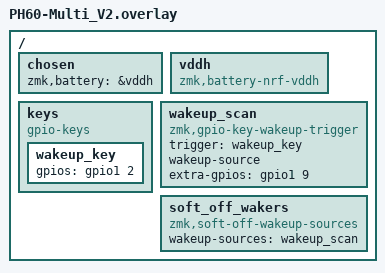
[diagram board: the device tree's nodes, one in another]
/*
 * Copyright (c) 2025 Team PHDesign
 *
 * SPDX-License-Identifier: MIT
 */

#include "PH60-Multi_V2.dtsi"


/ {
	chosen {
		zmk,battery = &vddh;
	};

	vddh: vddh {
		compatible = "zmk,battery-nrf-vddh";
	};

	keys {
		compatible = "gpio-keys";
		wakeup_key: wakeup_key {
			gpios = <&gpio1 2 (GPIO_ACTIVE_HIGH | GPIO_PULL_DOWN)>;  // Row 2
		};
	};

	wakeup_scan: wakeup_scan {
		compatible = "zmk,gpio-key-wakeup-trigger";
		trigger = <&wakeup_key>;
		wakeup-source;
		extra-gpios = <&gpio1 9 GPIO_ACTIVE_HIGH>;  // Column 12 (Enter)
	};

	soft_off_wakers {
		compatible = "zmk,soft-off-wakeup-sources";
		wakeup-sources = <&wakeup_scan>;
	};
};
